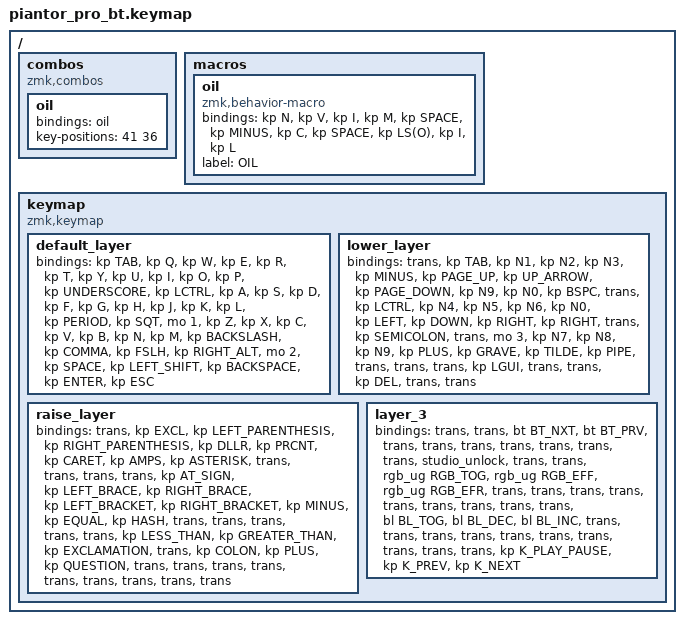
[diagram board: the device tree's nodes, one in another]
/*
 * Copyright (c) 2020 The ZMK Contributors
 *
 * SPDX-License-Identifier: MIT
 */

#include <behaviors.dtsi>
#include <dt-bindings/zmk/backlight.h>
#include <dt-bindings/zmk/bt.h>
#include <dt-bindings/zmk/keys.h>
#include <dt-bindings/zmk/rgb.h>

/ {
    combos {
        compatible = "zmk,combos";

        oil {
            bindings = <&oil>;
            key-positions = <41 36>;
        };
    };

    macros {
        oil: oil {
            compatible = "zmk,behavior-macro";
            #binding-cells = <0>;
            bindings = <&kp N &kp V &kp I &kp M &kp SPACE &kp MINUS &kp C &kp SPACE &kp LS(O) &kp I &kp L>;
            label = "OIL";
        };
    };

    keymap {
        compatible = "zmk,keymap";

        default_layer {
            // -----------------------------------------------------------------------------------------
            // |  TAB |  Q  |  W  |  E  |  R  |  T  |   |  Y  |  U   |  I  |  O  |  P  | BKSP |
            // | CTRL |  A  |  S  |  D  |  F  |  G  |   |  H  |  J   |  K  |  L  |  ;  |  '   |
            // | SHFT |  Z  |  X  |  C  |  V  |  B  |   |  N  |  M   |  ,  |  .  |  /  | ESC  |
            //                    | GUI | LWR | SPC |   | ENT | RSE  | ALT |

            bindings = <
&kp TAB  &kp Q  &kp W  &kp E  &kp R  &kp T  &kp Y  &kp U  &kp I  &kp O  &kp P  &kp UNDERSCORE  &kp LCTRL  &kp A  &kp S  &kp D  &kp F  &kp G  &kp H  &kp J  &kp K  &kp L  &kp PERIOD  &kp SQT  &mo 1  &kp Z  &kp X  &kp C  &kp V  &kp B  &kp N  &kp M  &kp BACKSLASH  &kp COMMA  &kp FSLH  &kp RIGHT_ALT  &mo 2  &kp SPACE  &kp LEFT_SHIFT  &kp BACKSPACE  &kp ENTER  &kp ESC
            >;
        };

        lower_layer {
            // -----------------------------------------------------------------------------------------
            // |  TAB |  1  |  2  |  3  |  4  |  5  |   |  6  |  7  |  8  |  9  |  0  | BKSP |
            // | BTCLR| BT1 | BT2 | BT3 | BT4 | BT5 |   | LFT | DWN |  UP | RGT |     |      |
            // | SHFT |     |     |     |     |     |   |     |     |     |     |     |      |
            //                    | GUI |     | SPC |   | ENT |     | ALT |

            bindings = <
&trans  &kp TAB  &kp N1  &kp N2  &kp N3  &kp MINUS  &kp PAGE_UP  &kp UP_ARROW  &kp PAGE_DOWN  &kp N9  &kp N0  &kp BSPC  &trans  &kp LCTRL  &kp N4  &kp N5  &kp N6  &kp N0  &kp LEFT  &kp DOWN  &kp RIGHT  &kp RIGHT  &trans  &kp SEMICOLON  &trans  &mo 3  &kp N7  &kp N8  &kp N9  &kp PLUS  &kp GRAVE  &kp TILDE  &kp PIPE  &trans  &trans  &trans  &kp LGUI  &trans  &trans  &kp DEL  &trans  &trans
            >;
        };

        raise_layer {
            // -----------------------------------------------------------------------------------------
            // |  TAB |  !  |  @  |  #  |  $  |  %  |   |  ^  |  &  |  *  |  (  |  )  | BKSP |
            // | CTRL |     |     |     |     |     |   |  -  |  =  |  [  |  ]  |  \  |  `   |
            // | SHFT |     |     |     |     |     |   |  _  |  +  |  {  |  }  | "|" |  ~   |
            //                    | GUI |     | SPC |   | ENT |     | ALT |

            bindings = <
&trans  &kp EXCL  &kp LEFT_PARENTHESIS  &kp RIGHT_PARENTHESIS  &kp DLLR  &kp PRCNT  &kp CARET  &kp AMPS  &kp ASTERISK  &trans  &trans  &trans  &trans  &kp AT_SIGN  &kp LEFT_BRACE  &kp RIGHT_BRACE  &kp LEFT_BRACKET  &kp RIGHT_BRACKET  &kp MINUS  &kp EQUAL  &kp HASH  &trans  &trans  &trans  &trans  &trans  &kp LESS_THAN  &kp GREATER_THAN  &kp EXCLAMATION  &trans  &kp COLON  &kp PLUS  &kp QUESTION  &trans  &trans  &trans  &trans  &trans  &trans  &trans  &trans  &trans
            >;
        };

        layer_3 {
            bindings = <
&trans  &trans  &bt BT_NXT  &bt BT_PRV  &trans  &trans  &trans  &trans  &trans  &trans  &trans  &studio_unlock  &trans  &trans  &rgb_ug RGB_TOG  &rgb_ug RGB_EFF  &rgb_ug RGB_EFR  &trans  &trans  &trans  &trans  &trans  &trans  &trans  &trans  &trans  &bl BL_TOG  &bl BL_DEC  &bl BL_INC  &trans  &trans  &trans  &trans  &trans  &trans  &trans  &trans  &trans  &trans  &kp K_PLAY_PAUSE  &kp K_PREV  &kp K_NEXT
            >;
        };
    };
};
